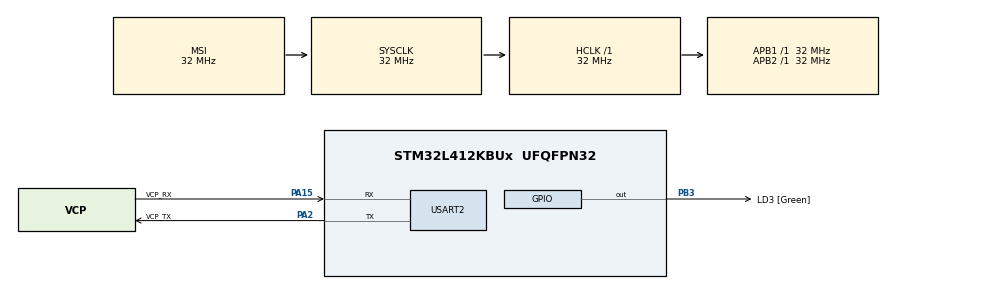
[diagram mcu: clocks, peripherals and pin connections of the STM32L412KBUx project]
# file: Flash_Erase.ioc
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Mcu.Family=STM32L4
Mcu.Name=STM32L412KBUx
Mcu.Package=UFQFPN32
NVIC.PriorityGroup=NVIC_PRIORITYGROUP_4
PA0-CK_IN.Mode=HSE-External-Clock-Source-for-LittleOrca
PA0-CK_IN.Signal=RCC_CK_IN
PA13\ (JTMS/SWDIO).GPIO_Label=SWDIO
PA13\ (JTMS/SWDIO).Mode=Serial_Wire
PA13\ (JTMS/SWDIO).Signal=SYS_JTMS-SWDIO
PA14\ (JTCK/SWCLK).GPIO_Label=SWCLK
PA14\ (JTCK/SWCLK).Mode=Serial_Wire
PA14\ (JTCK/SWCLK).Signal=SYS_JTCK-SWCLK
PA15\ (JTDI).GPIO_Label=VCP_RX
PA15\ (JTDI).Mode=Asynchronous
PA15\ (JTDI).Signal=USART2_RX
PA2.GPIO_Label=VCP_TX
PA2.Mode=Asynchronous
PA2.Signal=USART2_TX
PB3\ (JTDO/TRACESWO).GPIO_Label=LD3 [Green]
PB3\ (JTDO/TRACESWO).Signal=GPIO_Output
PC14-OSC32_IN\ (PC14).Mode=LSE-External-Oscillator
PC14-OSC32_IN\ (PC14).Signal=RCC_OSC32_IN
PC15-OSC32_OUT\ (PC15).Mode=LSE-External-Oscillator
PC15-OSC32_OUT\ (PC15).Signal=RCC_OSC32_OUT
ProjectManager.HeapSize=0x200
ProjectManager.StackSize=0x400
ProjectManager.TargetToolchain=STM32CubeIDE
RCC.ADCFreq_Value=32000000
RCC.AHBFreq_Value=32000000
RCC.APB1Freq_Value=32000000
RCC.APB1TimFreq_Value=32000000
RCC.APB2Freq_Value=32000000
RCC.APB2TimFreq_Value=32000000
RCC.CortexFreq_Value=32000000
RCC.FLatency=FLASH_LATENCY_1
RCC.HCLKFreq_Value=32000000
RCC.HSE_VALUE=8000000
RCC.HSI48_VALUE=48000000
RCC.HSICalibrationValue=64
RCC.HSI_VALUE=16000000
RCC.LSE_Drive_Capability=RCC_LSEDRIVE_LOW
RCC.MSIClockRange=RCC_MSIRANGE_10
RCC.MSI_VALUE=32000000
RCC.SYSCLKFreq_VALUE=32000000
RCC.USBFreq_Value=32000000
RCC.VCOOutputFreq_Value=256000000
USART2.VirtualMode-Asynchronous=VM_ASYNC
board=NUCLEO-L412KB

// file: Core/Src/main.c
/* USER CODE BEGIN Header */
/**
  ******************************************************************************
  * @file           : main.c
  * @brief          : Main program body
  ******************************************************************************
  * @attention
  *
  * Copyright (c) 2024 STMicroelectronics.
  * All rights reserved.
  *
  * This software is licensed under terms that can be found in the LICENSE file
  * in the root directory of this software component.
  * If no LICENSE file comes with this software, it is provided AS-IS.
  *
  ******************************************************************************
  */
/* USER CODE END Header */
#include "main.h"
#include "usart.h"
#include "gpio.h"

/* USER CODE BEGIN PD */
#define FLASH_USER_START_ADDR   ADDR_FLASH_PAGE_16   /* Start @ of user Flash area */
#define FLASH_USER_END_ADDR    0x08008800  /* End @ of user Flash area */

/* USER CODE END PD */

/* USER CODE BEGIN PV */
static FLASH_EraseInitTypeDef EraseInitStruct;

#define DATA_64                 ((uint64_t)0x1234567812345678)
#define DATA_32                 ((uint32_t)0x12345678)

uint32_t FirstPage = 0, NbOfPages = 0, BankNumber = 0;
uint32_t Address = 0, PAGEError = 0;
__IO uint32_t data32 = 0 , MemoryProgramStatus = 0;

/* USER CODE END PV */

void SystemClock_Config(void);
static uint32_t GetPage(uint32_t Address);
static uint32_t GetBank(uint32_t Address);

int main(void)
{

  /* MCU Configuration--------------------------------------------------------*/

  /* Reset of all peripherals, Initializes the Flash interface and the Systick. */
  HAL_Init();

  /* Configure the system clock */
  SystemClock_Config();

  /* Initialize all configured peripherals */
  MX_GPIO_Init();
  MX_USART2_UART_Init();
  /* USER CODE BEGIN 2 */

  // 플래시 메모리 Unlock
  HAL_FLASH_Unlock();

  /* Get the 1st page to erase */
  FirstPage = GetPage(FLASH_USER_START_ADDR);

  /* Get the number of pages to erase from 1st page */
  NbOfPages = GetPage(FLASH_USER_END_ADDR) - FirstPage + 1;

  /* Get the bank */
  BankNumber = GetBank(FLASH_USER_START_ADDR);

  /* Fill EraseInit structure*/
  EraseInitStruct.TypeErase   = FLASH_TYPEERASE_PAGES;
  EraseInitStruct.Banks       = BankNumber;
  EraseInitStruct.Page        = FirstPage;
  EraseInitStruct.NbPages     = NbOfPages;

  if (HAL_FLASHEx_Erase(&EraseInitStruct, &PAGEError) != HAL_OK)
  {
    /*
      Error occurred while page erase.
      User can add here some code to deal with this error.
      PAGEError will contain the faulty page and then to know the code error on this page,
      user can call function 'HAL_FLASH_GetError()'
    */

  }

  // 다시 Address를 시작주소로 보낸다
    Address = FLASH_USER_START_ADDR;

    while (Address < FLASH_USER_END_ADDR)
     {
       if (HAL_FLASH_Program(FLASH_TYPEPROGRAM_DOUBLEWORD, Address, DATA_64) == HAL_OK)
       {
         Address = Address + 8;
       }
      else
       {
         /* Error occurred while writing data in Flash memory.
            User can add here some code to deal with this error */

       }
     }

    /* Lock the Flash to disable the flash control register access (recommended
       to protect the FLASH memory against possible unwanted operation) *********/
    HAL_FLASH_Lock();

  /* USER CODE END 2 */

  /* Infinite loop */
  while (1)
  {

  }
}

void SystemClock_Config(void)
{
  RCC_OscInitTypeDef RCC_OscInitStruct = {0};
  RCC_ClkInitTypeDef RCC_ClkInitStruct = {0};

  /** Configure the main internal regulator output voltage
  */
  if (HAL_PWREx_ControlVoltageScaling(PWR_REGULATOR_VOLTAGE_SCALE1) != HAL_OK)
  {
    Error_Handler();
  }

  /** Configure LSE Drive Capability
  */
  HAL_PWR_EnableBkUpAccess();
  __HAL_RCC_LSEDRIVE_CONFIG(RCC_LSEDRIVE_LOW);

  /** Initializes the RCC Oscillators according to the specified parameters
  * in the RCC_OscInitTypeDef structure.
  */
  RCC_OscInitStruct.OscillatorType = RCC_OSCILLATORTYPE_LSE|RCC_OSCILLATORTYPE_MSI;
  RCC_OscInitStruct.LSEState = RCC_LSE_ON;
  RCC_OscInitStruct.MSIState = RCC_MSI_ON;
  RCC_OscInitStruct.MSICalibrationValue = 0;
  RCC_OscInitStruct.MSIClockRange = RCC_MSIRANGE_10;
  RCC_OscInitStruct.PLL.PLLState = RCC_PLL_NONE;
  if (HAL_RCC_OscConfig(&RCC_OscInitStruct) != HAL_OK)
  {
    Error_Handler();
  }

  /** Initializes the CPU, AHB and APB buses clocks
  */
  RCC_ClkInitStruct.ClockType = RCC_CLOCKTYPE_HCLK|RCC_CLOCKTYPE_SYSCLK
                              |RCC_CLOCKTYPE_PCLK1|RCC_CLOCKTYPE_PCLK2;
  RCC_ClkInitStruct.SYSCLKSource = RCC_SYSCLKSOURCE_MSI;
  RCC_ClkInitStruct.AHBCLKDivider = RCC_SYSCLK_DIV1;
  RCC_ClkInitStruct.APB1CLKDivider = RCC_HCLK_DIV1;
  RCC_ClkInitStruct.APB2CLKDivider = RCC_HCLK_DIV1;

  if (HAL_RCC_ClockConfig(&RCC_ClkInitStruct, FLASH_LATENCY_1) != HAL_OK)
  {
    Error_Handler();
  }

  /** Enable MSI Auto calibration
  */
  HAL_RCCEx_EnableMSIPLLMode();
}

/* USER CODE BEGIN 4 */
static uint32_t GetPage(uint32_t Addr)
{
  uint32_t page = 0;

  if (Addr < (FLASH_BASE + FLASH_BANK_SIZE))
  {
    /* Bank 1 */
    page = (Addr - FLASH_BASE) / FLASH_PAGE_SIZE;
  }
  else
  {
    /* Bank 2 */
    page = (Addr - (FLASH_BASE + FLASH_BANK_SIZE)) / FLASH_PAGE_SIZE;
  }

  return page;
}

/**
  * @brief  Gets the bank of a given address
  * @param  Addr: Address of the FLASH Memory
  * @retval The bank of a given address
  */
static uint32_t GetBank(uint32_t Addr)
{
  return FLASH_BANK_1;
}

/* USER CODE END 4 */

void Error_Handler(void)
{
  __disable_irq();
  while (1)
  {
  }
}
